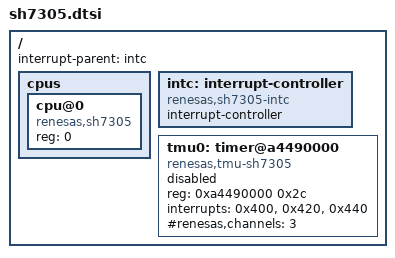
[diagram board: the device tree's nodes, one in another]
// SPDX-License-Identifier: GPL-2.0-only
// Copyright (C) 2026 Artem Novak

/ {
	interrupt-parent = <&intc>;
	#address-cells = <1>;
	#size-cells = <1>;

	cpus {
		#address-cells = <1>;
		#size-cells = <0>;

		cpu@0 {
			device_type = "cpu";
			compatible = "renesas,sh7305";
			reg = <0>;
		};
	};

	intc: interrupt-controller {
		compatible = "renesas,sh7305-intc";
		interrupt-controller;
		#interrupt-cells = <1>;
	};

	/*
	 * SH7305 TMU0: three timer channels.
	 *
	 * Keep disabled while the SH early-platform timer owns this
	 * hardware. Clock provider integration is still required.
	 */
	tmu0: timer@a4490000 {
		compatible = "renesas,tmu-sh7305", "renesas,tmu";
		reg = <0xa4490000 0x2c>;
		interrupts = <0x400>, <0x420>, <0x440>;
		interrupt-names = "tuni0", "tuni1", "tuni2";
		#renesas,channels = <3>;
		status = "disabled";
	};
};
